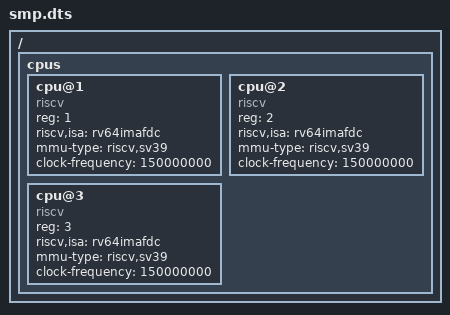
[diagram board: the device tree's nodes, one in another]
/* SPDX-License-Identifier: GPL-2.0-only */
/ { cpus {
    cpu@1 {
        device_type = "cpu"; reg = <1>; status = "okay";
        compatible = "riscv"; riscv,isa = "rv64imafdc";
        mmu-type = "riscv,sv39"; clock-frequency = <150000000>;
    };
    cpu@2 {
        device_type = "cpu"; reg = <2>; status = "okay";
        compatible = "riscv"; riscv,isa = "rv64imafdc";
        mmu-type = "riscv,sv39"; clock-frequency = <150000000>;
    };
    cpu@3 {
        device_type = "cpu"; reg = <3>; status = "okay";
        compatible = "riscv"; riscv,isa = "rv64imafdc";
        mmu-type = "riscv,sv39"; clock-frequency = <150000000>;
    };
}; };
